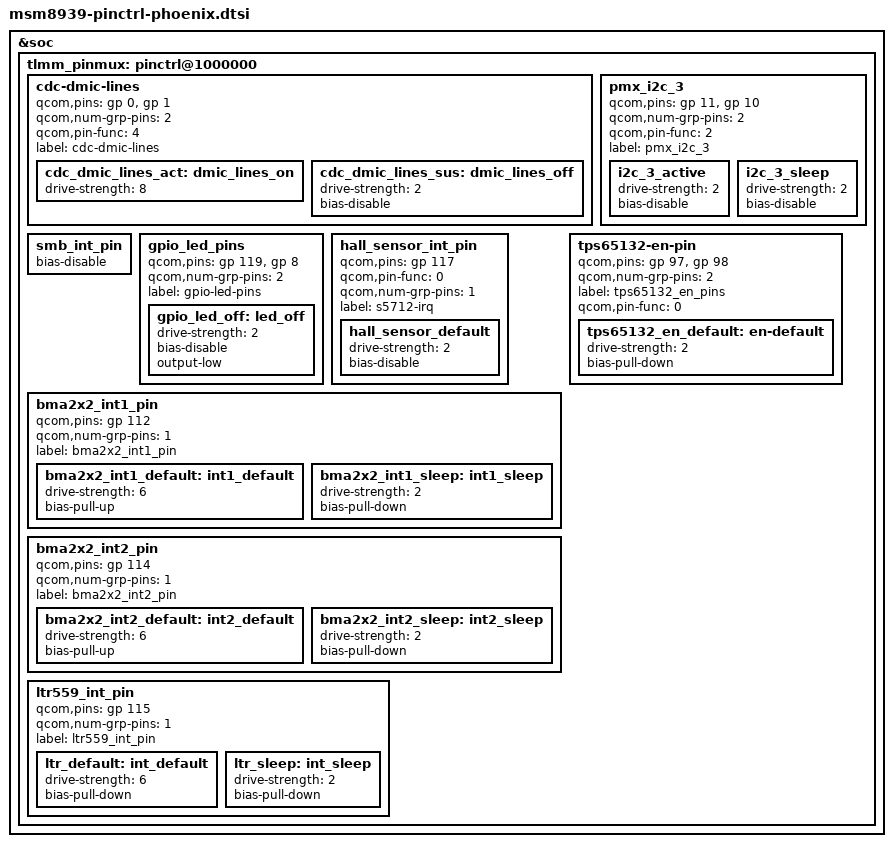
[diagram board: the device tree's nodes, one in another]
/* Copyright (c) 2015, The Linux Foundation. All rights reserved.
 *
 * This program is free software; you can redistribute it and/or modify
 * it under the terms of the GNU General Public License version 2 and
 * only version 2 as published by the Free Software Foundation.
 *
 * This program is distributed in the hope that it will be useful,
 * but WITHOUT ANY WARRANTY; without even the implied warranty of
 * MERCHANTABILITY or FITNESS FOR A PARTICULAR PURPOSE.  See the
 * GNU General Public License for more details.
 */

#include "../msm8939-pinctrl.dtsi"

&soc {
	tlmm_pinmux: pinctrl@1000000 {
		cdc-dmic-lines {
			qcom,pins = <&gp 0>, <&gp 1>;
			qcom,num-grp-pins = <2>;
			qcom,pin-func = <4>;
			label = "cdc-dmic-lines";
			cdc_dmic_lines_act: dmic_lines_on {
				drive-strength = <8>;
			};
			cdc_dmic_lines_sus: dmic_lines_off {
				drive-strength = <2>;
				bias-disable;
			};
		};

		pmx_i2c_3 {
			/* CLK, DATA */
			qcom,pins = <&gp 11>, <&gp 10>;
			qcom,num-grp-pins = <2>;
			qcom,pin-func = <2>;
			label = "pmx_i2c_3";
			i2c_3_active: i2c_3_active {
				drive-strength = <2>; /* 2 MA */
				bias-disable;         /* No PULL */
			};
			i2c_3_sleep: i2c_3_sleep {
				drive-strength = <2>; /* 2 MA */
				bias-disable;	      /* No PULL */
			};
		};

		smb_int_pin {
			/delete-property/ bias-pull-up;
			bias-disable;
		};

		gpio_led_pins {
			qcom,pins = <&gp 119>, <&gp 8>;
			qcom,num-grp-pins = <2>;
			label = "gpio-led-pins";
			gpio_led_off: led_off {
				drive-strength = <2>;
				bias-disable;
				output-low;
			};
		};

		hall_sensor_int_pin {
			qcom,pins = <&gp 117>;
			qcom,pin-func = <0>;
			qcom,num-grp-pins = <1>;
			label = "s5712-irq";
			hall_sensor_default: hall_sensor_default {
				drive-strength = <2>;
				bias-disable; 
			};
		};

		bma2x2_int1_pin {
			qcom,pins = <&gp 112>;
			qcom,num-grp-pins = <1>;
			label = "bma2x2_int1_pin";
			bma2x2_int1_default: int1_default {
				drive-strength = <6>;
				bias-pull-up;
			};
			bma2x2_int1_sleep: int1_sleep {
				drive-strength = <2>;
				bias-pull-down;
			};
		};

		bma2x2_int2_pin {
			qcom,pins = <&gp 114>;
			qcom,num-grp-pins = <1>;
			label = "bma2x2_int2_pin";
			bma2x2_int2_default: int2_default {
				drive-strength = <6>;
				bias-pull-up;
			};
			bma2x2_int2_sleep: int2_sleep {
				drive-strength = <2>;
				bias-pull-down;
			};
		};

		ltr559_int_pin {
			qcom,pins = <&gp 115>;
			qcom,num-grp-pins = <1>;
			label = "ltr559_int_pin";
			ltr_default: int_default {
				drive-strength = <6>;
				bias-pull-down;
			};
			ltr_sleep: int_sleep {
				drive-strength = <2>;
				bias-pull-down;
			};
		};

		tps65132-en-pin {
			qcom,pins = <&gp 97>, <&gp 98>;
			qcom,num-grp-pins = <2>;
			label = "tps65132_en_pins";
			qcom,pin-func = <0>;

			tps65132_en_default: en-default {
				drive-strength = <2>;
				bias-pull-down;
			};
		};

		/delete-node/ spi0_active;
		/delete-node/ spi0_suspend;
		/delete-node/ spi0_cs0_active;
		/delete-node/ spi0_cs0_suspend;
		/delete-node/ apds99xx_int_pin;
		/delete-node/ mpu6050_int_pin;
		/delete-node/ ak8963_int_pin;
	};
};
